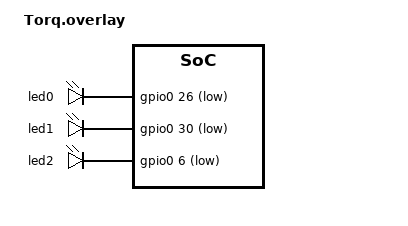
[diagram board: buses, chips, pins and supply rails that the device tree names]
#include <dt-bindings/zmk/bt.h>
#include <input/processors.dtsi>
#include <dt-bindings/zmk/input_transform.h>
#include "Torq_pinctrl.dtsi"
#include "Torq.dtsi"
#include <dt-bindings/zmk/matrix_transform.h>
#include <behaviors/rgbled_widget.dtsi>

/ {
    chosen {
        zephyr,display = &oled;
    };

    default_transform: keymap_transform_0 {
      compatible = "zmk,matrix-transform";
      columns = <4>;
      rows = <1>;

      map = <
        RC(0,0)   RC(0,1)   RC(0,2)   RC(0,3)
        >;
    };
    
    aliases {
        led-red = &led0;
        led-green = &led1;
        led-blue = &led2;
    };

    leds {
        compatible = "gpio-leds";
        status = "okay";
        led0: led_0 {
            gpios = <&gpio0 26 GPIO_ACTIVE_LOW>;  // red LED, connected to P0.26
        };
        led1: led_1 {
            gpios = <&gpio0 30 GPIO_ACTIVE_LOW>;  // green LED, connected to P0.30
        };
        led2: led_2 {
            gpios = <&gpio0 6 GPIO_ACTIVE_LOW>;  // blue LED, connected to P0.06
        };
    };

    trackball_listener {
        status = "okay";
        compatible = "zmk,input-listener";
        device = <&trackball>;
        input-processors = <&zip_temp_layer 3 1000>;
        scroll {
            layers = <2>;
            input-processors = <&zip_xy_transform (INPUT_TRANSFORM_Y_INVERT)>, <&zip_xy_scaler 1 16>, <&zip_xy_to_scroll_mapper>;
        };
    };
}; 
